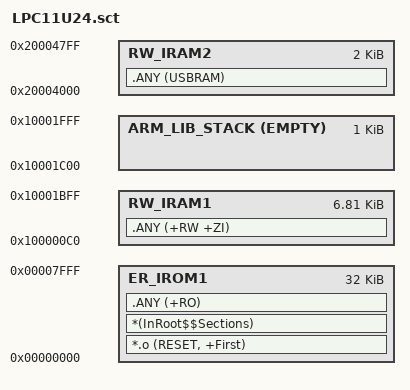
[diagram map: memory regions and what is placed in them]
#! armcc -E

#if !defined(MBED_BOOT_STACK_SIZE)
  #define MBED_BOOT_STACK_SIZE 0x400
#endif

#define Stack_Size MBED_BOOT_STACK_SIZE

LR_IROM1 0x00000000 0x8000  {    ; load region size_region (32k)
  ER_IROM1 0x00000000 0x8000  {  ; load address = execution address
   *.o (RESET, +First)
   *(InRoot$$Sections)
   .ANY (+RO)
  }
  ; 8_byte_aligned(48 vect * 4 bytes) =  8_byte_aligned(0xC0) = 0xC0
  ; 8KB - 0xC0 = 0x1F40
  RW_IRAM1 0x100000C0 0x1F40-Stack_Size  {
   .ANY (+RW +ZI)
  }
  ARM_LIB_STACK (0x100000C0+0x1F40) EMPTY -Stack_Size { ; stack
  }
  RW_IRAM2 0x20004000 0x800   { ; RW data, USB RAM
   .ANY (USBRAM)
  }
}

